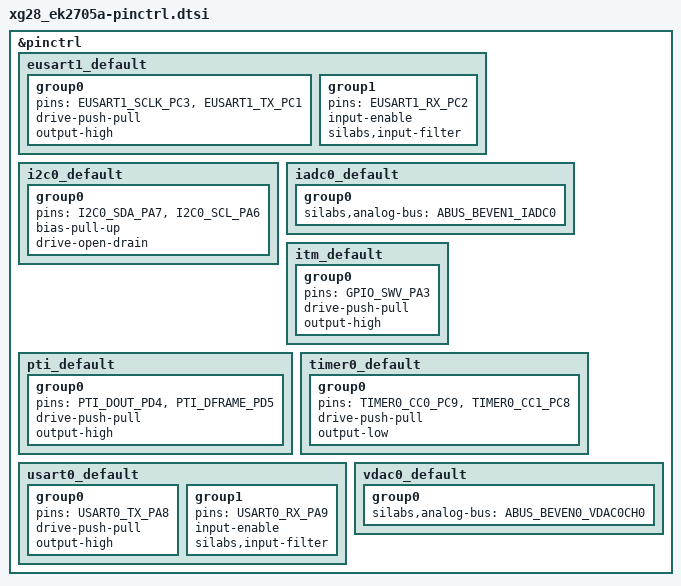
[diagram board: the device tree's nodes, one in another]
/*
 * Copyright (c) 2026 Silicon Laboratories Inc.
 *
 * SPDX-License-Identifier: Apache-2.0
 */
#include <zephyr/dt-bindings/pinctrl/silabs/xg28-pinctrl.h>

&pinctrl {
	eusart1_default: eusart1_default {
		group0 {
			pins = <EUSART1_SCLK_PC3>, <EUSART1_TX_PC1>;
			drive-push-pull;
			output-high;
		};

		group1 {
			pins = <EUSART1_RX_PC2>;
			input-enable;
			silabs,input-filter;
		};
	};

	i2c0_default: i2c0_default {
		group0 {
			pins = <I2C0_SDA_PA7>, <I2C0_SCL_PA6>;
			bias-pull-up;
			drive-open-drain;
		};
	};

	iadc0_default: iadc0_default {
		group0 {
			silabs,analog-bus = <ABUS_BEVEN1_IADC0>;
		};
	};

	itm_default: itm_default {
		group0 {
			pins = <GPIO_SWV_PA3>;
			drive-push-pull;
			output-high;
		};
	};

	pti_default: pti_default {
		group0 {
			pins = <PTI_DOUT_PD4>, <PTI_DFRAME_PD5>;
			drive-push-pull;
			output-high;
		};
	};

	timer0_default: timer0_default {
		group0 {
			pins = <TIMER0_CC0_PC9>, <TIMER0_CC1_PC8>;
			drive-push-pull;
			output-low;
		};
	};

	usart0_default: usart0_default {
		group0 {
			pins = <USART0_TX_PA8>;
			drive-push-pull;
			output-high;
		};

		group1 {
			pins = <USART0_RX_PA9>;
			input-enable;
			silabs,input-filter;
		};
	};

	vdac0_default: vdac0_default {
		group0 {
			silabs,analog-bus = <ABUS_BEVEN0_VDAC0CH0>;
		};
	};
};
